AUTOSAR XML (schema 4-3-0)
package /CompositionARPkgName
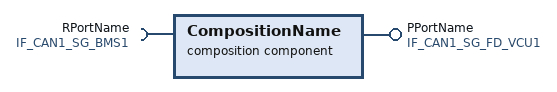
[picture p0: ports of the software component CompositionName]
  composition sw component type CompositionName
    require port RPortName: nonqueued-receiver-com-spec{data-element=CAN1_SG_BMS1, handle-out-of-range=DEFAULT, enable-update=true, init-value=constant-reference=Init_CAN1_SG_BMS1}, required-interface=IF_CAN1_SG_BMS1
    provide port PPortName: nonqueued-sender-com-spec{data-element=CAN1_SG_FD_VCU1, handle-out-of-range=DEFAULT, init-value=constant-reference=Init_CAN1_SG_FD_VCU1}, provided-interface=IF_CAN1_SG_FD_VCU1
    4 x component:
      SWC_AppStateHandler: type=SWC_AppStateHandler_type
      SWC_CDD_ZONE_DR: type=SWC_CDD_ZONE_DR_type
      SWC_CGW: type=SWC_CGW_type
      SWC_ZONE_DR: type=SWC_ZONE_DR_type
    delegate SWC_FDC.R_CAN1_FCM3 <-> outer port HALR_CAN1_FCM3
    delegate SWC_FDC.P_CAN3_FD_VCU1 <-> outer port HALP_CAN3_FD_VCU1
    connect SWC_CDD_ZONE_DR.P_HALINCDD -> SWC_ZONE_DR.R_HALINCDD
    connect SWC_CDD_ZONE_DR.P_HALOUTCDD -> SWC_ZONE_DR.R_HALOUTCDD
